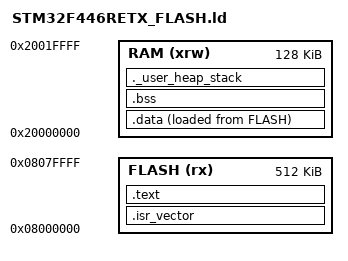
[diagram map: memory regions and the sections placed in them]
ENTRY(Reset_Handler)

MEMORY
{
  FLASH (rx) : ORIGIN = 0x08000000, LENGTH = 512K
  RAM (xrw)  : ORIGIN = 0x20000000, LENGTH = 128K
}

_estack = ORIGIN(RAM) + LENGTH(RAM);

SECTIONS
{
  .isr_vector :
  {
    KEEP(*(.isr_vector))
  } > FLASH

  .text :
  {
    *(.text*)
    *(.rodata*)
    . = ALIGN(4);
    PROVIDE_HIDDEN (__preinit_array_start = .);
    KEEP (*(.preinit_array*))
    PROVIDE_HIDDEN (__preinit_array_end = .);
    . = ALIGN(4);
    PROVIDE_HIDDEN (__init_array_start = .);
    KEEP (*(SORT(.init_array.*)))
    KEEP (*(.init_array*))
    PROVIDE_HIDDEN (__init_array_end = .);
    . = ALIGN(4);
    PROVIDE_HIDDEN (__fini_array_start = .);
    KEEP (*(SORT(.fini_array.*)))
    KEEP (*(.fini_array*))
    PROVIDE_HIDDEN (__fini_array_end = .);
  } > FLASH

  .data :
  {
    _sdata = .;
    *(.data*)
    _edata = .;
  } > RAM AT > FLASH
  _sidata = LOADADDR(.data);

  .bss :
  {
    _sbss = .;
    *(.bss*)
    *(COMMON)
    _ebss = .;
  } > RAM

  /* newlib/libnosys expects this symbol for _sbrk default stub */
  PROVIDE(end = _ebss);

  ._user_heap_stack :
  {
    . = ALIGN(8);
    . = . + 0x1000;
  } > RAM
}
